# iospear300 register map
Registers from a debugger description file.
Registers are 32-bit, access not given, no defined reset value unless marked. A register's access mark holds for its fields unless they carry their own. Addresses are absolute; registers are grouped by the start of their names; lines under a group give offsets from that group; [hi:lo] are bit positions; {n}, {i} and the like mark numbered series; 'fields as' and 'values as' point back to an identical list; <NAME> marks a mode.

## PLL1
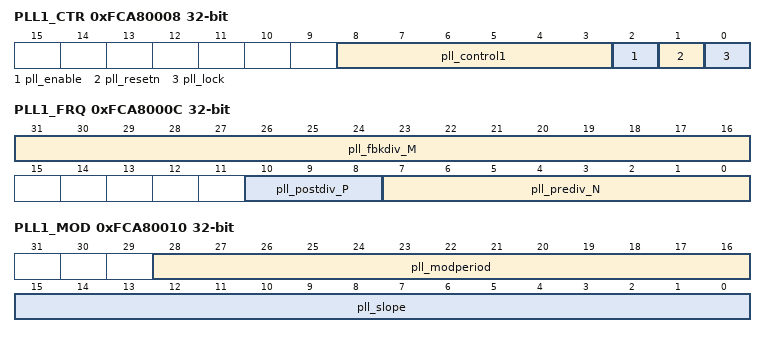
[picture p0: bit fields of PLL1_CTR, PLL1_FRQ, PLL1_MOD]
0xFCA80008 PLL1_CTR
  [8:3] pll_control1, [2] pll_enable, [1] pll_resetn, [0] pll_lock
0xFCA8000C PLL1_FRQ
  [31:16] pll_fbkdiv_M, [10:8] pll_postdiv_P, [7:0] pll_prediv_N
0xFCA80010 PLL1_MOD
  [28:16] pll_modperiod, [15:0] pll_slope

## PLL2
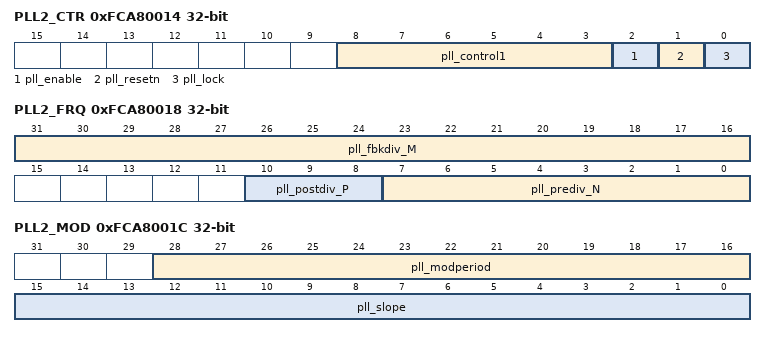
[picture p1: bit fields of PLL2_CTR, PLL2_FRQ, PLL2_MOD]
0xFCA80014 PLL2_CTR
  [8:3] pll_control1, [2] pll_enable, [1] pll_resetn, [0] pll_lock
0xFCA80018 PLL2_FRQ
  [31:16] pll_fbkdiv_M, [10:8] pll_postdiv_P, [7:0] pll_prediv_N
0xFCA8001C PLL2_MOD
  [28:16] pll_modperiod, [15:0] pll_slope

## PERIP1
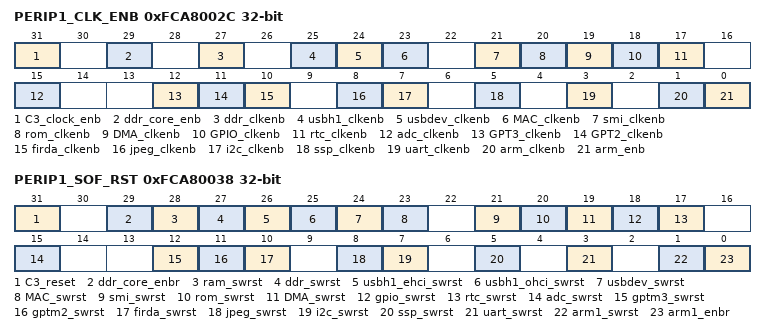
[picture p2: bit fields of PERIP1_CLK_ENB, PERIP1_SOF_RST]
0xFCA8002C PERIP1_CLK_ENB
  [31] C3_clock_enb, [29] ddr_core_enb, [27] ddr_clkenb, [25] usbh1_clkenb, [24] usbdev_clkenb, [23] MAC_clkenb, [21] smi_clkenb, [20] rom_clkenb, [19] DMA_clkenb, [18] GPIO_clkenb, [17] rtc_clkenb, [15] adc_clkenb, [12] GPT3_clkenb, [11] GPT2_clkenb, [10] firda_clkenb, [8] jpeg_clkenb, [7] i2c_clkenb, [5] ssp_clkenb, [3] uart_clkenb, [1] arm_clkenb, [0] arm_enb
0xFCA80038 PERIP1_SOF_RST
  [31] C3_reset, [29] ddr_core_enbr, [28] ram_swrst, [27] ddr_swrst, [26] usbh1_ehci_swrst, [25] usbh1_ohci_swrst, [24] usbdev_swrst, [23] MAC_swrst, [21] smi_swrst, [20] rom_swrst, [19] DMA_swrst, [18] gpio_swrst, [17] rtc_swrst, [15] adc_swrst, [12] gptm3_swrst, [11] gptm2_swrst, [10] firda_swrst, [8] jpeg_swrst, [7] i2c_swrst, [5] ssp_swrst, [3] uart_swrst, [1] arm1_swrst, [0] arm1_enbr

## RAS
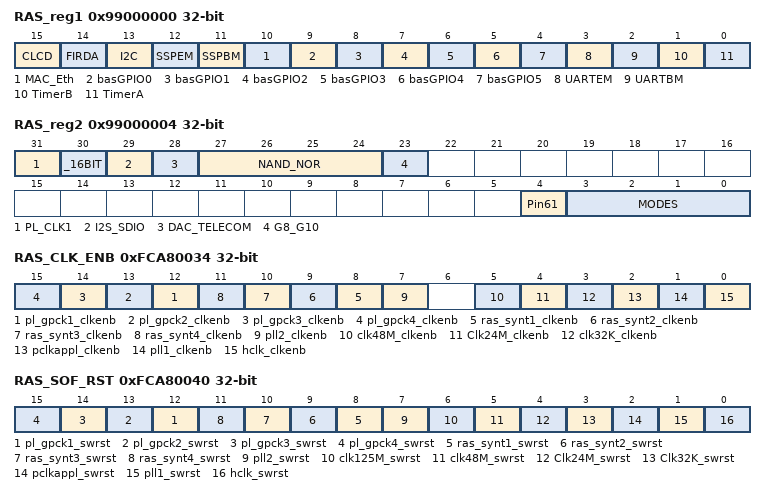
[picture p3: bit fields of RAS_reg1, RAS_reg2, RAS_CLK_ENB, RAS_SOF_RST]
0x99000000 RAS_reg1
  [15] CLCD, [14] FIRDA, [13] I2C, [12] SSPEM, [11] SSPBM, [10] MAC_Eth, [9-n] basGPIO{n} (n=0..5), [3] UARTEM, [2] UARTBM, [1] TimerB, [0] TimerA
0x99000004 RAS_reg2
  [31] PL_CLK1, [30] _16BIT, [29] I2S_SDIO, [28] DAC_TELECOM, [27:24] NAND_NOR, [23] G8_G10, [4] Pin61, [3:0] MODES
0xFCA80034 RAS_CLK_ENB
  [n+11] pl_gpck{n}_clkenb (n=1..4), [n+7] ras_synt{n}_clkenb (n=1..4), [7] pll2_clkenb, [5] clk48M_clkenb, [4] Clk24M_clkenb, [3] clk32K_clkenb, [2] pclkappl_clkenb, [1] pll1_clkenb, [0] hclk_clkenb
0xFCA80040 RAS_SOF_RST
  [n+11] pl_gpck{n}_swrst (n=1..4), [n+7] ras_synt{n}_swrst (n=1..4), [7] pll2_swrst, [6] clk125M_swrst, [5] clk48M_swrst, [4] Clk24M_swrst, [3] Clk32K_swrst, [2] pclkappl_swrst, [1] pll1_swrst, [0] hclk_swrst

## MAC
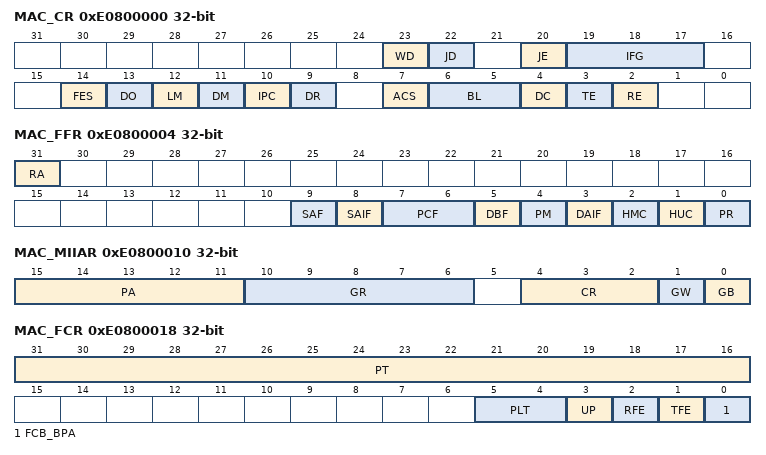
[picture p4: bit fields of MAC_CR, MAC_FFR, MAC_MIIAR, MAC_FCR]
0xE0800000 MAC_CR
  [23] WD, [22] JD, [20] JE, [19:17] IFG, [14] FES, [13] DO, [12] LM, [11] DM, [10] IPC, [9] DR, [7] ACS, [6:5] BL, [4] DC, [3] TE, [2] RE
0xE0800004 MAC_FFR
  [31] RA, [9] SAF, [8] SAIF, [7:6] PCF, [5] DBF, [4] PM, [3] DAIF, [2] HMC, [1] HUC, [0] PR
0xE0800008 MAC_HTHR
0xE080000C MAC_HTLR
0xE0800010 MAC_MIIAR
  [15:11] PA, [10:6] GR, [4:2] CR, [1] GW, [0] GB
0xE0800014 MAC_MIIDR
  [15:0] GD
0xE0800018 MAC_FCR
  [31:16] PT, [5:4] PLT, [3] UP, [2] RFE, [1] TFE, [0] FCB_BPA
0xE080001C MAC_VLANTR
  [15:0] VL
0xE0800020 MAC_VR
  [7:0] VER
0xE0800028 MAC_PTWUFFR
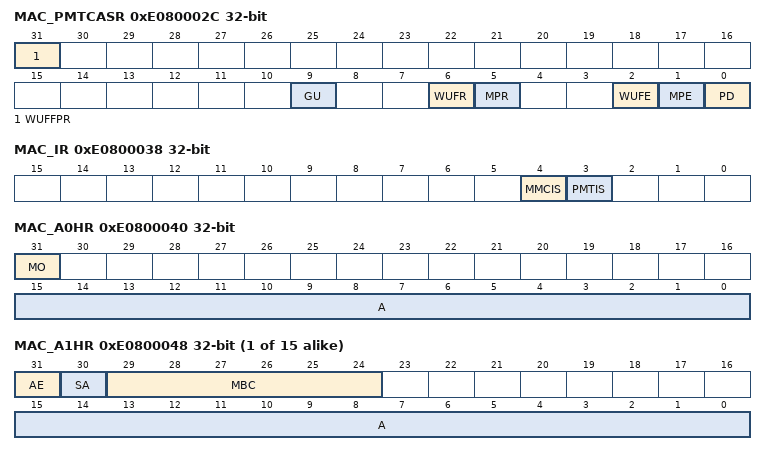
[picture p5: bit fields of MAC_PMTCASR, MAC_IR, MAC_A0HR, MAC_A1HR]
0xE080002C MAC_PMTCASR
  [31] WUFFPR, [9] GU, [6] WUFR, [5] MPR, [2] WUFE, [1] MPE, [0] PD
0xE0800038 MAC_IR
  [4] MMCIS, [3] PMTIS
0xE080003C MAC_IMR
  [3] PMTIM
0xE0800040 MAC_A0HR
  [31] MO, [15:0] A
{0xE0800044+8i} MAC_A{i}LR (i=0..15)
{0xE0800040+8i} MAC_A{i}HR (i=1..15)
  [31] AE, [30] SA, [29:24] MBC, [15:0] A
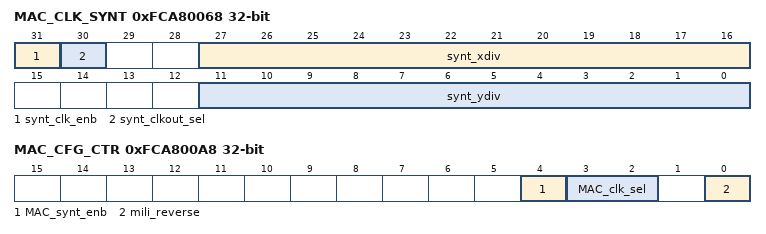
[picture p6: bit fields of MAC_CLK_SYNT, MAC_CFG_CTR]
0xFCA80068 MAC_CLK_SYNT
  [31] synt_clk_enb, [30] synt_clkout_sel, [27:16] synt_xdiv, [11:0] synt_ydiv
0xFCA800A8 MAC_CFG_CTR
  [4] MAC_synt_enb, [3:2] MAC_clk_sel, [0] mili_reverse
